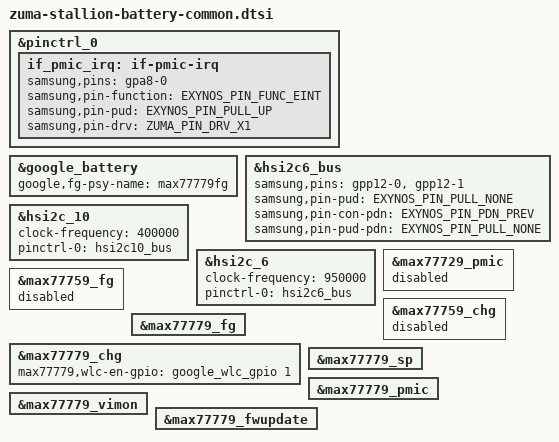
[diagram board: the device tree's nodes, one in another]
// SPDX-License-Identifier: GPL-2.0-only
/*
 * Battery device tree entries for Zuma24
 *
 * Copyright 2024 Google LLC
 *
 */

#include "zuma/zuma-battery.dtsi"
#include "zuma/zuma-max777xx_fwupdate.dtsi"

&pinctrl_0 {
/* [MAX77729FEWN : INTB] > IF_PMIC_IRQ_L > [XEINT_22 : SC59845XWE] */
	if_pmic_irq: if-pmic-irq {
		samsung,pins = "gpa8-0";
		samsung,pin-function = <EXYNOS_PIN_FUNC_EINT>;
		samsung,pin-pud = <EXYNOS_PIN_PULL_UP>;
		samsung,pin-drv = <ZUMA_PIN_DRV_X1>;
	};

};

&google_battery {
	google,fg-psy-name = "max77779fg";
};

&hsi2c6_bus {
	samsung,pins = "gpp12-0", "gpp12-1";
	samsung,pin-pud = <EXYNOS_PIN_PULL_NONE>;
	samsung,pin-con-pdn = <EXYNOS_PIN_PDN_PREV>;
	samsung,pin-pud-pdn = <EXYNOS_PIN_PULL_NONE>;
};

&hsi2c_10 {
	#address-cells = <1>;
	#size-cells = <0>;
	status = "okay";
	clock-frequency = <400000>;

	pinctrl-names = "default";
	pinctrl-0 = <&hsi2c10_bus>;

	#include "zuma/zuma-max777xx-eeprom.dtsi"
};

&hsi2c_6 {

	#address-cells = <1>;
	#size-cells = <0>;
	status = "okay";
	clock-frequency = <950000>;
	pinctrl-0 = <&hsi2c6_bus>;

	#include "zuma/zuma-max777xx.dtsi"
};

&max77729_pmic {
	status = "disabled";
};

&max77759_fg {
	status = "disabled";
};

&max77759_chg {
	status = "disabled";
};

&max77779_fg {
	status = "okay";
};

&max77779_chg {
	status = "okay";
	max77779,wlc-en-gpio = <&google_wlc_gpio 1 GPIO_ACTIVE_HIGH>;
};

&max77779_sp {
	status = "okay";
};

&max77779_pmic {
	status = "okay";
};

&max77779_vimon {
	status = "okay";
};

&max77779_fwupdate {
	status = "okay";
};

